# CMSDK_ARMv8MML_DP register map
Vendor: ARM Ltd.; Series: ARMv8-M Mainline; File version: 1.0
ARM 32-bit v8-M Mainline based device
CPU: ARMV8MML r0p0, little endian, MPU, FPU, double-precision FPU, 3 interrupt priority bits, 4 SAU regions
Registers are 32-bit, read-write, reset 0x0 unless marked. A register's access mark holds for its fields unless they carry their own. Offsets are from the block's base; lines under a group give offsets from that group; [hi:lo] are bit positions; {n}, {i} and the like mark numbered series; 'fields as' and 'values as' point back to an identical list; <NAME> marks a mode.

## Memory map
0x40000000 TIMER0 size 0x10 — Timer 0 (Non-Secure)
0x40001000 TIMER1 size 0x10
0x40002000 DUALTIMER size 0x3C
0x40004000 UART0 size 0x14
0x40005000 UART1 size 0x14
0x40006000 UART2 size 0x14
0x40007000 UART3 size 0x14
0x40008000 WDT size 0xC04 — Watchdog Timer
0x40009000 UART4 size 0x14
0x40010000 GPIO0 size 0x3C — general-purpose I/O
0x40011000 GPIO1 size 0x3C
0x40027000 SPI size 0x40
0x40028000 FPGAIO size 0x100 — FPGA System Control I/O
0x4002F000 SCC size 0x1000 — Serial Communication Controller
0x50000000 SECURETIMER0 size 0x10
0x50001000 SECURETIMER1 size 0x10
0xE000EDD0 SAU size 0x20 — Security Attribution Unit

## Interrupts
0 UART0_RX (UART0) — UART 0 Receive Interrupt
0 WDT — Watchdog Interrupt
2 UART1_RX (UART1) — UART 1 Receive Interrupt
4 UART2_RX (UART2) — UART 1 Receive Interrupt
6 GPIO0 — GPIO 0 combined interrupt
7 GPIO1 — GPIO 1 combined interrupt
8 TIMER0 — Timer 0 Interrupt
9 TIMER1 — Timer 1 Interrupt
10 DUALTIMER — Dual Timer Interrupt
11 SPI — Combined SPI 0, SPI 1 Interrupt
18 UART3_RX (UART3) — UART 3 Receive Interrupt
20 UART4_RX (UART4) — UART 4 Receive Interrupt
50 SECURETIMER0 — Secure Timer 0 Interrupt
51 SECURETIMER1 — Secure Timer 0 Interrupt

## SAU — Security Attribution Unit
Base 0xE000EDD0
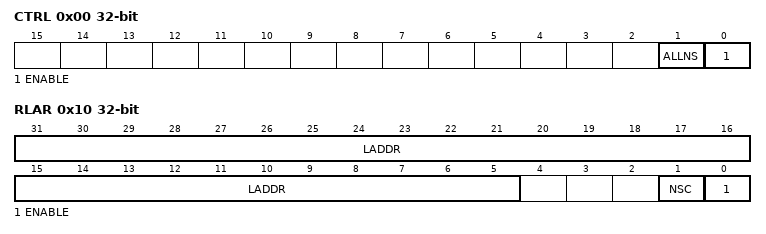
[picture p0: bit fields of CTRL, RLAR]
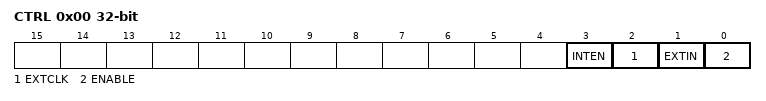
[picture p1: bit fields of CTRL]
0x00 CTRL — Control Register
  [1] ALLNS — Security attribution if SAU disabled
    0=Secure (Memory is marked as secure); 1=Non_Secure (Memory is marked as non-secure)
  [0] ENABLE
    0=Disable (SAU is disabled); 1=Enable (SAU is enabled)
0x04 TYPE ro
  [7:0] SREGION — Number of implemented SAU regions
0x08 RNR — Region Number Register
  [7:0] REGION — Currently selected SAU region
    {v}=SAU_Region_{v} (Select SAU Region {v}) (v=0..3)
0x0C RBAR — Region Base Address Register
  [31:5] BADDR — Base Address
0x10 RLAR — Region Limit Address Register
  [31:5] LADDR — Limit Address
  [1] NSC — Non-Secure Callable
  [0] ENABLE — SAU Region enabled

## TIMER0 — Timer 0 (Non-Secure)
Base 0x40000000
Same registers: TIMER1 0x40001000, SECURETIMER0 0x50000000, SECURETIMER1 0x50001000
0x00 CTRL — Control Register
  [3] INTEN — Interrupt Enable
    0=Disable (Interrupt is disabled); 1=Enable (Interrupt is enabled)
  [2] EXTCLK — External Clock Enable
    0=Disable (External Clock s disabled); 1=Enable (External Clock is enabled)
  [1] EXTIN — External Input as Enable
    0=Disable (External Input as Enable is disabled); 1=Enable (External Input as Enable is enabled)
  [0] ENABLE
    0=Disable (Timer is disabled); 1=Enable (Timer is enabled)
0x04 VALUE — Current Timer Counter Value
0x08 RELOAD — Counter Reload Value
0x0C INTSTATUS ro — Timer Interrupt status register
0x0C INTCLEAR wo write-1-clears (alternate view of INTSTATUS) — Timer Interrupt clear register

## Licence text in the file
ARM Limited (ARM) is supplying this software for use with Cortex-M processor based microcontroller, but can be equally used for other suitable processor architectures. This file can be freely distributed. Modifications to this file shall be clearly marked. . THIS SOFTWARE IS PROVIDED "AS IS". NO WARRANTIES, WHETHER EXPRESS, IMPLIED. OR STATUTORY, INCLUDING, BUT NOT LIMITED TO, IMPLIED WARRANTIES OF. MERCHANTABILITY AND FITNESS FOR A PARTICULAR PURPOSE APPLY TO THIS SOFTWARE. ARM SHALL NOT, IN ANY CIRCUMSTANCES, BE LIABLE FOR SPECIAL, INCIDENTAL, OR. CONSEQUENTIAL DAMAGES, FOR ANY REASON WHATSOEVER.

## Notices in the file
Copyright (C) 2012-2014 ARM Limited. All rights reserved.
Purpose: System Viewer Description (SVD) Example (Schema Version 1.1)
This is a description of a none-existent and incomplete device
for demonstration purposes only.
Redistribution and use in source and binary forms, with or without
modification, are permitted provided that the following conditions are met:
- Redistributions of source code must retain the above copyright
notice, this list of conditions and the following disclaimer.
- Redistributions in binary form must reproduce the above copyright
notice, this list of conditions and the following disclaimer in the
documentation and/or other materials provided with the distribution.
- Neither the name of ARM nor the names of its contributors may be used
to endorse or promote products derived from this software without
specific prior written permission.
THIS SOFTWARE IS PROVIDED BY THE COPYRIGHT HOLDERS AND CONTRIBUTORS "AS IS"
AND ANY EXPRESS OR IMPLIED WARRANTIES, INCLUDING, BUT NOT LIMITED TO, THE
ARE DISCLAIMED. IN NO EVENT SHALL COPYRIGHT HOLDERS AND CONTRIBUTORS BE
LIABLE FOR ANY DIRECT, INDIRECT, INCIDENTAL, SPECIAL, EXEMPLARY, OR
CONSEQUENTIAL DAMAGES (INCLUDING, BUT NOT LIMITED TO, PROCUREMENT OF
SUBSTITUTE GOODS OR SERVICES; LOSS OF USE, DATA, OR PROFITS; OR BUSINESS
INTERRUPTION) HOWEVER CAUSED AND ON ANY THEORY OF LIABILITY, WHETHER IN
CONTRACT, STRICT LIABILITY, OR TORT (INCLUDING NEGLIGENCE OR OTHERWISE)
ARISING IN ANY WAY OUT OF THE USE OF THIS SOFTWARE, EVEN IF ADVISED OF THE
POSSIBILITY OF SUCH DAMAGE.
